# ATSAMA5D28CLD1G device description
Architecture: CORTEX-A5; Family: SAMA5; Series: SAMA5D2
Registers are 32-bit, read-write, no defined reset value unless marked. A register's access mark holds for its fields unless they carry their own. Offsets are from the block's base; [hi:lo] are bit positions; lines under a group give offsets from that group; {n}, {i} and the like mark numbered series; 'fields as' and 'values as' point back to an identical list; <NAME> marks a mode.

## UDPHS — USB High Speed Device Port
Instances: UDPHS 0xFC02C000
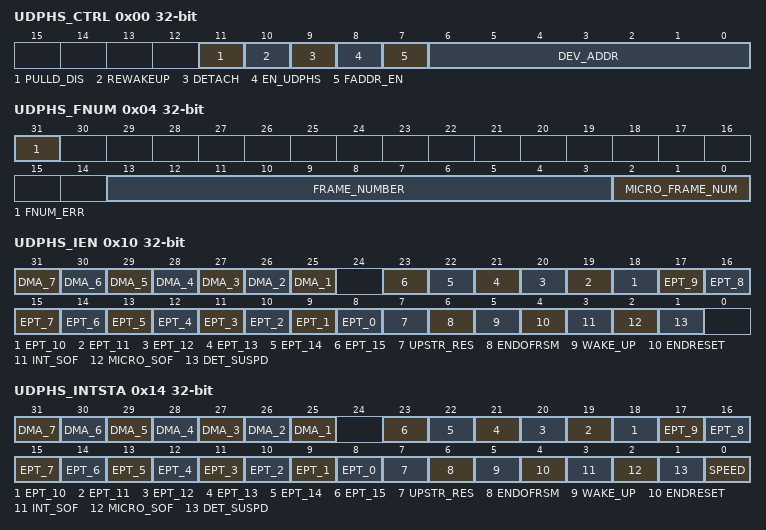
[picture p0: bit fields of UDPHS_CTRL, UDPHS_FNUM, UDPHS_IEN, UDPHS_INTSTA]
0x00 UDPHS_CTRL — UDPHS Control Register
  [11] PULLD_DIS — Pulldown Disable (cleared upon USB reset)
  [10] REWAKEUP — Send Remote Wakeup (cleared upon USB reset)
  [9] DETACH — Detach Command
  [8] EN_UDPHS — UDPHS Enable
  [7] FADDR_EN — Function Address Enable (cleared upon USB reset)
  [6:0] DEV_ADDR — UDPHS Address (cleared upon USB reset)
0x04 UDPHS_FNUM ro — UDPHS Frame Number Register
  [31] FNUM_ERR — Frame Number CRC Error (cleared upon USB reset)
  [13:3] FRAME_NUMBER — Frame Number as defined in the Packet Field Formats (cleared upon USB reset)
  [2:0] MICRO_FRAME_NUM — Microframe Number (cleared upon USB reset)
0x10 UDPHS_IEN — UDPHS Interrupt Enable Register
  [n+24] DMA_{n} (n=1..7) — DMA Channel {n} Interrupt Enable (cleared upon USB reset)
  [n+8] EPT_{n} (n=0..15) — Endpoint {n} Interrupt Enable (cleared upon USB reset)
  [7] UPSTR_RES — Upstream Resume Interrupt Enable (cleared upon USB reset)
  [6] ENDOFRSM — End Of Resume Interrupt Enable (cleared upon USB reset)
  [5] WAKE_UP — Wake Up CPU Interrupt Enable (cleared upon USB reset)
  [4] ENDRESET — End Of Reset Interrupt Enable (cleared upon USB reset)
  [3] INT_SOF — SOF Interrupt Enable (cleared upon USB reset)
  [2] MICRO_SOF — Micro-SOF Interrupt Enable (cleared upon USB reset)
  [1] DET_SUSPD — Suspend Interrupt Enable (cleared upon USB reset)
0x14 UDPHS_INTSTA ro — UDPHS Interrupt Status Register
  [n+24] DMA_{n} (n=1..7) — DMA Channel {n} Interrupt
  [n+8] EPT_{n} (n=0..15) — Endpoint {n} Interrupt (cleared upon USB reset)
  [7] UPSTR_RES — Upstream Resume Interrupt
  [6] ENDOFRSM — End Of Resume Interrupt
  [5] WAKE_UP — Wake Up CPU Interrupt
  [4] ENDRESET — End Of Reset Interrupt
  [3] INT_SOF — Start Of Frame Interrupt
  [2] MICRO_SOF — Micro Start Of Frame Interrupt
  [1] DET_SUSPD — Suspend Interrupt
  [0] SPEED — Speed Status
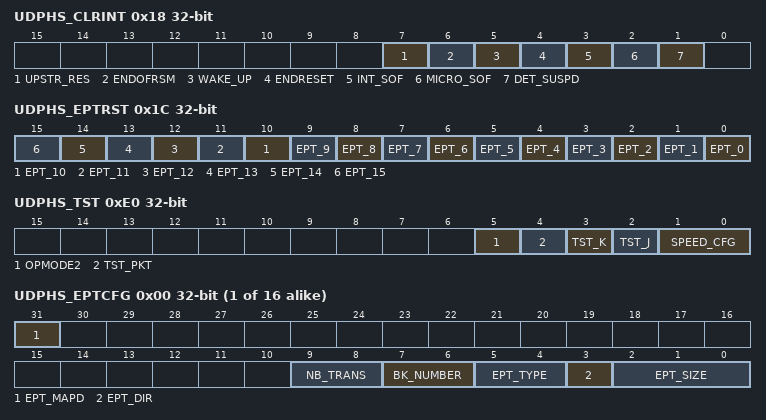
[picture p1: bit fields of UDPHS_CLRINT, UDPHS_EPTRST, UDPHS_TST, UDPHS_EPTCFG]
0x18 UDPHS_CLRINT wo — UDPHS Clear Interrupt Register
  [7] UPSTR_RES — Upstream Resume Interrupt Clear
  [6] ENDOFRSM — End Of Resume Interrupt Clear
  [5] WAKE_UP — Wake Up CPU Interrupt Clear
  [4] ENDRESET — End Of Reset Interrupt Clear
  [3] INT_SOF — Start Of Frame Interrupt Clear
  [2] MICRO_SOF — Micro Start Of Frame Interrupt Clear
  [1] DET_SUSPD — Suspend Interrupt Clear
0x1C UDPHS_EPTRST wo — UDPHS Endpoints Reset Register
  [n] EPT_{n} (n=0..15) — Endpoint {n} Reset
0xE0 UDPHS_TST — UDPHS Test Register
  [5] OPMODE2
  [4] TST_PKT — Test Packet Mode
  [3] TST_K — Test K Mode
  [2] TST_J — Test J Mode
  [1:0] SPEED_CFG — Speed Configuration
    0=NORMAL (Normal mode: The macro is in Full Speed mode, ready to make a High Speed identification, if the host supports it and then to automatically switch to High Speed mode.); 2=HIGH_SPEED (Force High Speed: Set this value to force the hardware to work in High Speed mode. Only for debug or test purpose.); 3=FULL_SPEED (Force Full Speed: Set this value to force the hardware to work only in Full Speed mode. In this configuration, the macro will not respond to a High Speed reset handshake.)
0xEC UDPHS_ADDRSIZE ro — UDPHS IP Address Size Register
  [31:0] ADDRSIZE — Peripheral Bus Address Size
{0xF0+4i} UDPHS_IPNAME[{i}] (i=0..1) ro — UDPHS IP Name1 Register
  [31:0] IPNAME — IP Name in ASCII Format
0xF8 UDPHS_FEATURES ro
{0x100+0x20*i} UDPHS_EPT[{i}] (i=0..15) group
  0x00 UDPHS_EPTCFG — UDPHS Endpoint Configuration Register (endpoint = 0)
    [31] EPT_MAPD — Endpoint Mapped (cleared upon USB reset)
    [9:8] NB_TRANS — Number Of Transaction per Microframe (cleared upon USB reset)
    [7:6] BK_NUMBER — Number of Banks (cleared upon USB reset)
      0=Zero bank, the endpoint is not mapped in memory; 1=One bank (bank 0); 2=Double bank (Ping-Pong: bank0/bank1); 3=Triple bank (bank0/bank1/bank2)
    [5:4] EPT_TYPE — Endpoint Type (cleared upon USB reset)
      0=CTRL8 (Control endpoint); 1=ISO (Isochronous endpoint); 2=BULK (Bulk endpoint); 3=INT (Interrupt endpoint)
    [3] EPT_DIR — Endpoint Direction (cleared upon USB reset)
    [2:0] EPT_SIZE — Endpoint Size (cleared upon USB reset)
      0=8 bytes; 1=16 bytes; 2=32 bytes; 3=64 bytes; 4=128 bytes; 5=256 bytes; 6=512 bytes; 7=1024 bytes
  0x04 UDPHS_EPTCTLENB wo (modes: DEFAULT when UDPHS_EPT.EPT_TYPE=0x0 0x2 0x3; ISOENDPT when UDPHS_EPT.EPT_TYPE=0x1) — UDPHS Endpoint Control Enable Register (endpoint = 0)
    [31] SHRT_PCKT <DEFAULT> — Short Packet Send/Short Packet Interrupt Enable
    [18] BUSY_BANK <DEFAULT> — Busy Bank Interrupt Enable
    [15] NAK_OUT <DEFAULT> — NAKOUT Interrupt Enable
    [14] NAK_IN <DEFAULT> — NAKIN Interrupt Enable
    [13] STALL_SNT <DEFAULT> — Stall Sent Interrupt Enable
    [12] RX_SETUP <DEFAULT> — Received SETUP
    [11] TXRDY <DEFAULT> — TX Packet Ready Interrupt Enable
    [10] TX_COMPLT <DEFAULT> — Transmitted IN Data Complete Interrupt Enable
    [9] RXRDY_TXKL <DEFAULT> — Received OUT Data Interrupt Enable
    [8] ERR_OVFLW <DEFAULT> — Overflow Error Interrupt Enable
    [4] NYET_DIS <DEFAULT> — NYET Disable (Only for High Speed Bulk OUT endpoints)
    [3] INTDIS_DMA <DEFAULT> — Interrupts Disable DMA
    [1] AUTO_VALID <DEFAULT> — Packet Auto-Valid Enable
    [0] EPT_ENABL <DEFAULT> — Endpoint Enable
    [31] SHRT_PCKT <ISOENDPT> — Short Packet Send/Short Packet Interrupt Enable
    [18] BUSY_BANK <ISOENDPT> — Busy Bank Interrupt Enable
    [14] ERR_FLUSH <ISOENDPT> — Bank Flush Error Interrupt Enable
    [13] ERR_CRC_NTR <ISOENDPT> — ISO CRC Error/Number of Transaction Error Interrupt Enable
    [12] ERR_FL_ISO <ISOENDPT> — Error Flow Interrupt Enable
    [11] TXRDY_TRER <ISOENDPT> — TX Packet Ready/Transaction Error Interrupt Enable
    [10] TX_COMPLT <ISOENDPT> — Transmitted IN Data Complete Interrupt Enable
    [9] RXRDY_TXKL <ISOENDPT> — Received OUT Data Interrupt Enable
    [8] ERR_OVFLW <ISOENDPT> — Overflow Error Interrupt Enable
    [7] MDATA_RX <ISOENDPT> — MDATA Interrupt Enable (Only for high bandwidth Isochronous OUT endpoints)
    [6] DATAX_RX <ISOENDPT> — DATAx Interrupt Enable (Only for high bandwidth Isochronous OUT endpoints)
    [3] INTDIS_DMA <ISOENDPT> — Interrupts Disable DMA
    [1] AUTO_VALID <ISOENDPT> — Packet Auto-Valid Enable
    [0] EPT_ENABL <ISOENDPT> — Endpoint Enable
  0x08 UDPHS_EPTCTLDIS wo (modes: DEFAULT when UDPHS_EPT.EPT_TYPE=0x0 0x2 0x3; ISOENDPT when UDPHS_EPT.EPT_TYPE=0x1) — UDPHS Endpoint Control Disable Register (endpoint = 0)
    [31] SHRT_PCKT <DEFAULT> — Short Packet Interrupt Disable
    [18] BUSY_BANK <DEFAULT> — Busy Bank Interrupt Disable
    [15] NAK_OUT <DEFAULT> — NAKOUT Interrupt Disable
    [14] NAK_IN <DEFAULT> — NAKIN Interrupt Disable
    [13] STALL_SNT <DEFAULT> — Stall Sent Interrupt Disable
    [12] RX_SETUP <DEFAULT> — Received SETUP Interrupt Disable
    [11] TXRDY <DEFAULT> — TX Packet Ready Interrupt Disable
    [10] TX_COMPLT <DEFAULT> — Transmitted IN Data Complete Interrupt Disable
    [9] RXRDY_TXKL <DEFAULT> — Received OUT Data Interrupt Disable
    [8] ERR_OVFLW <DEFAULT> — Overflow Error Interrupt Disable
    [4] NYET_DIS <DEFAULT> — NYET Enable (Only for High Speed Bulk OUT endpoints)
    [3] INTDIS_DMA <DEFAULT> — Interrupts Disable DMA
    [1] AUTO_VALID <DEFAULT> — Packet Auto-Valid Disable
    [0] EPT_DISABL <DEFAULT> — Endpoint Disable
    [31] SHRT_PCKT <ISOENDPT> — Short Packet Interrupt Disable
    [18] BUSY_BANK <ISOENDPT> — Busy Bank Interrupt Disable
    [14] ERR_FLUSH <ISOENDPT> — bank flush error Interrupt Disable
    [13] ERR_CRC_NTR <ISOENDPT> — ISO CRC Error/Number of Transaction Error Interrupt Disable
    [12] ERR_FL_ISO <ISOENDPT> — Error Flow Interrupt Disable
    [11] TXRDY_TRER <ISOENDPT> — TX Packet Ready/Transaction Error Interrupt Disable
    [10] TX_COMPLT <ISOENDPT> — Transmitted IN Data Complete Interrupt Disable
    [9] RXRDY_TXKL <ISOENDPT> — Received OUT Data Interrupt Disable
    [8] ERR_OVFLW <ISOENDPT> — Overflow Error Interrupt Disable
    [7] MDATA_RX <ISOENDPT> — MDATA Interrupt Disable (Only for High Bandwidth Isochronous OUT endpoints)
    [6] DATAX_RX <ISOENDPT> — DATAx Interrupt Disable (Only for High Bandwidth Isochronous OUT endpoints)
    [3] INTDIS_DMA <ISOENDPT> — Interrupts Disable DMA
    [1] AUTO_VALID <ISOENDPT> — Packet Auto-Valid Disable
    [0] EPT_DISABL <ISOENDPT> — Endpoint Disable
  0x0C UDPHS_EPTCTL ro (modes: DEFAULT when UDPHS_EPT.EPT_TYPE=0x0 0x2 0x3; ISOENDPT when UDPHS_EPT.EPT_TYPE=0x1) — UDPHS Endpoint Control Register (endpoint = 0)
    [31] SHRT_PCKT <DEFAULT> — Short Packet Interrupt Enabled (cleared upon USB reset)
    [18] BUSY_BANK <DEFAULT> — Busy Bank Interrupt Enabled (cleared upon USB reset)
    [15] NAK_OUT <DEFAULT> — NAKOUT Interrupt Enabled (cleared upon USB reset)
    [14] NAK_IN <DEFAULT> — NAKIN Interrupt Enabled (cleared upon USB reset)
    [13] STALL_SNT <DEFAULT> — Stall Sent Interrupt Enabled (cleared upon USB reset)
    [12] RX_SETUP <DEFAULT> — Received SETUP Interrupt Enabled (cleared upon USB reset)
    [11] TXRDY <DEFAULT> — TX Packet Ready Interrupt Enabled (cleared upon USB reset)
    [10] TX_COMPLT <DEFAULT> — Transmitted IN Data Complete Interrupt Enabled (cleared upon USB reset)
    [9] RXRDY_TXKL <DEFAULT> — Received OUT Data Interrupt Enabled (cleared upon USB reset)
    [8] ERR_OVFLW <DEFAULT> — Overflow Error Interrupt Enabled (cleared upon USB reset)
    [4] NYET_DIS <DEFAULT> — NYET Disable (Only for High Speed Bulk OUT Endpoints) (cleared upon USB reset)
    [3] INTDIS_DMA <DEFAULT> — Interrupt Disables DMA (cleared upon USB reset)
    [1] AUTO_VALID <DEFAULT> — Packet Auto-Valid Enabled (Not for CONTROL Endpoints) (cleared upon USB reset)
    [0] EPT_ENABL <DEFAULT> — Endpoint Enable (cleared upon USB reset)
    [31] SHRT_PCKT <ISOENDPT> — Short Packet Interrupt Enabled (cleared upon USB reset)
    [18] BUSY_BANK <ISOENDPT> — Busy Bank Interrupt Enabled (cleared upon USB reset)
    [14] ERR_FLUSH <ISOENDPT> — Bank Flush Error Interrupt Enabled (cleared upon USB reset)
    [13] ERR_CRC_NTR <ISOENDPT> — ISO CRC Error/Number of Transaction Error Interrupt Enabled (cleared upon USB reset)
    [12] ERR_FL_ISO <ISOENDPT> — Error Flow Interrupt Enabled (cleared upon USB reset)
    [11] TXRDY_TRER <ISOENDPT> — TX Packet Ready/Transaction Error Interrupt Enabled (cleared upon USB reset)
    [10] TX_COMPLT <ISOENDPT> — Transmitted IN Data Complete Interrupt Enabled (cleared upon USB reset)
    [9] RXRDY_TXKL <ISOENDPT> — Received OUT Data Interrupt Enabled (cleared upon USB reset)
    [8] ERR_OVFLW <ISOENDPT> — Overflow Error Interrupt Enabled (cleared upon USB reset)
    [7] MDATA_RX <ISOENDPT> — MDATA Interrupt Enabled (Only for High Bandwidth Isochronous OUT endpoints) (cleared upon USB reset)
    [6] DATAX_RX <ISOENDPT> — DATAx Interrupt Enabled (Only for High Bandwidth Isochronous OUT endpoints) (cleared upon USB reset)
    [3] INTDIS_DMA <ISOENDPT> — Interrupt Disables DMA (cleared upon USB reset)
    [1] AUTO_VALID <ISOENDPT> — Packet Auto-Valid Enabled (cleared upon USB reset)
    [0] EPT_ENABL <ISOENDPT> — Endpoint Enable (cleared upon USB reset)
  0x14 UDPHS_EPTSETSTA wo (modes: DEFAULT when UDPHS_EPT.EPT_TYPE=0x0 0x2 0x3; ISOENDPT when UDPHS_EPT.EPT_TYPE=0x1) — UDPHS Endpoint Set Status Register (endpoint = 0)
    [11] TXRDY <DEFAULT> — TX Packet Ready Set
    [9] RXRDY_TXKL <DEFAULT> — KILL Bank Set (for IN Endpoint)
    [5] FRCESTALL <DEFAULT> — Stall Handshake Request Set
    [11] TXRDY_TRER <ISOENDPT> — TX Packet Ready Set
    [9] RXRDY_TXKL <ISOENDPT> — KILL Bank Set (for IN Endpoint)
  0x18 UDPHS_EPTCLRSTA wo (modes: DEFAULT when UDPHS_EPT.EPT_TYPE=0x0 0x2 0x3; ISOENDPT when UDPHS_EPT.EPT_TYPE=0x1) — UDPHS Endpoint Clear Status Register (endpoint = 0)
    [15] NAK_OUT <DEFAULT> — NAKOUT Clear
    [14] NAK_IN <DEFAULT> — NAKIN Clear
    [13] STALL_SNT <DEFAULT> — Stall Sent Clear
    [12] RX_SETUP <DEFAULT> — Received SETUP Clear
    [10] TX_COMPLT <DEFAULT> — Transmitted IN Data Complete Clear
    [9] RXRDY_TXKL <DEFAULT> — Received OUT Data Clear
    [6] TOGGLESQ <DEFAULT> — Data Toggle Clear
    [5] FRCESTALL <DEFAULT> — Stall Handshake Request Clear
    [14] ERR_FLUSH <ISOENDPT> — Bank Flush Error Clear
    [13] ERR_CRC_NTR <ISOENDPT> — Number of Transaction Error Clear
    [12] ERR_FL_ISO <ISOENDPT> — Error Flow Clear
    [10] TX_COMPLT <ISOENDPT> — Transmitted IN Data Complete Clear
    [9] RXRDY_TXKL <ISOENDPT> — Received OUT Data Clear
    [6] TOGGLESQ <ISOENDPT> — Data Toggle Clear
  0x1C UDPHS_EPTSTA ro (modes: DEFAULT when UDPHS_EPT.EPT_TYPE=0x0 0x2 0x3; ISOENDPT when UDPHS_EPT.EPT_TYPE=0x1) — UDPHS Endpoint Status Register (endpoint = 0)
    [31] SHRT_PCKT <DEFAULT> — Short Packet (cleared upon USB reset)
    [30:20] BYTE_COUNT <DEFAULT> — UDPHS Byte Count (cleared upon USB reset)
    [19:18] BUSY_BANK_STA <DEFAULT> — Busy Bank Number (cleared upon USB reset)
      0=_0BUSYBANK (All banks are free); 1=_1BUSYBANK; 2=_2BUSYBANKS; 3=_3BUSYBANKS
    [17:16] CURBK_CTLDIR <DEFAULT> — Current Bank/Control Direction (cleared upon USB reset)
    [15] NAK_OUT <DEFAULT> — NAK OUT (cleared upon USB reset)
    [14] NAK_IN <DEFAULT> — NAK IN (cleared upon USB reset)
    [13] STALL_SNT <DEFAULT> — Stall Sent (cleared upon USB reset)
    [12] RX_SETUP <DEFAULT> — Received SETUP (cleared upon USB reset)
    [11] TXRDY <DEFAULT> — TX Packet Ready (cleared upon USB reset)
    [10] TX_COMPLT <DEFAULT> — Transmitted IN Data Complete (cleared upon USB reset)
    [9] RXRDY_TXKL <DEFAULT> — Received OUT Data/KILL Bank (cleared upon USB reset)
    [8] ERR_OVFLW <DEFAULT> — Overflow Error (cleared upon USB reset)
    [7:6] TOGGLESQ_STA <DEFAULT> — Toggle Sequencing (cleared upon USB reset)
      0=DATA0; 1=DATA1; 2=DATA2 (Reserved for High Bandwidth Isochronous Endpoint); 3=MDATA (Reserved for High Bandwidth Isochronous Endpoint)
    [5] FRCESTALL <DEFAULT> — Stall Handshake Request (cleared upon USB reset)
    [31] SHRT_PCKT <ISOENDPT> — Short Packet (cleared upon USB reset)
    [30:20] BYTE_COUNT <ISOENDPT> — UDPHS Byte Count (cleared upon USB reset)
    [19:18] BUSY_BANK_STA <ISOENDPT> — Busy Bank Number (cleared upon USB reset)
      values as BUSY_BANK_STA<DEFAULT>
    [17:16] CURBK <ISOENDPT> — Current Bank (cleared upon USB reset)
      0=BANK0 (Bank 0 (or single bank)); 1=BANK1; 2=BANK2
    [14] ERR_FLUSH <ISOENDPT> — Bank Flush Error (cleared upon USB reset)
    [13] ERR_CRC_NTR <ISOENDPT> — CRC ISO Error/Number of Transaction Error (cleared upon USB reset)
    [12] ERR_FL_ISO <ISOENDPT> — Error Flow (cleared upon USB reset)
    [11] TXRDY_TRER <ISOENDPT> — TX Packet Ready/Transaction Error (cleared upon USB reset)
    [10] TX_COMPLT <ISOENDPT> — Transmitted IN Data Complete (cleared upon USB reset)
    [9] RXRDY_TXKL <ISOENDPT> — Received OUT Data/KILL Bank (cleared upon USB reset)
    [8] ERR_OVFLW <ISOENDPT> — Overflow Error (cleared upon USB reset)
    [7:6] TOGGLESQ_STA <ISOENDPT> — Toggle Sequencing (cleared upon USB reset)
      0=DATA0; 1=DATA1; 2=DATA2 (Data2 (only for High Bandwidth Isochronous Endpoint)); 3=MDATA (MData (only for High Bandwidth Isochronous Endpoint))
{0x300+0x10*i} UDPHS_DMA[{i}] (i=0..6) group
  0x00 UDPHS_DMANXTDSC — UDPHS DMA Next Descriptor Address Register (channel = 0)
    [31:0] NXT_DSC_ADD — Next Descriptor Address
  0x04 UDPHS_DMAADDRESS — UDPHS DMA Channel Address Register (channel = 0)
    [31:0] BUFF_ADD — Buffer Address
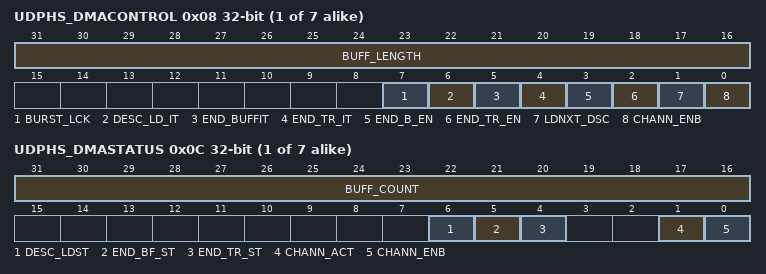
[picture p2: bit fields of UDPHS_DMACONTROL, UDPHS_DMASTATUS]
  0x08 UDPHS_DMACONTROL — UDPHS DMA Channel Control Register (channel = 0)
    [31:16] BUFF_LENGTH — Buffer Byte Length (Write-only)
    [7] BURST_LCK — Burst Lock Enable
    [6] DESC_LD_IT — Descriptor Loaded Interrupt Enable
    [5] END_BUFFIT — End of Buffer Interrupt Enable
    [4] END_TR_IT — End of Transfer Interrupt Enable
    [3] END_B_EN — End of Buffer Enable (Control)
    [2] END_TR_EN — End of Transfer Enable (Control)
    [1] LDNXT_DSC — Load Next Channel Transfer Descriptor Enable (Command)
    [0] CHANN_ENB — (Channel Enable Command)
  0x0C UDPHS_DMASTATUS — UDPHS DMA Channel Status Register (channel = 0)
    [31:16] BUFF_COUNT — Buffer Byte Count
    [6] DESC_LDST — Descriptor Loaded Status
    [5] END_BF_ST — End of Channel Buffer Status
    [4] END_TR_ST — End of Channel Transfer Status
    [1] CHANN_ACT — Channel Active Status
    [0] CHANN_ENB — Channel Enable Status

## Notices in the file
Copyright (c) 2020 Microchip Technology Inc.
SPDX-License-Identifier: Apache-2.0
Licensed under the Apache License, Version 2.0 (the "License");
you may not use this file except in compliance with the License.
You may obtain a copy of the License at
http://www.apache.org/licenses/LICENSE-2.0
Unless required by applicable law or agreed to in writing, software
distributed under the License is distributed on an "AS IS" BASIS,
WITHOUT WARRANTIES OR CONDITIONS OF ANY KIND, either express or implied.
See the License for the specific language governing permissions and
limitations under the License.
